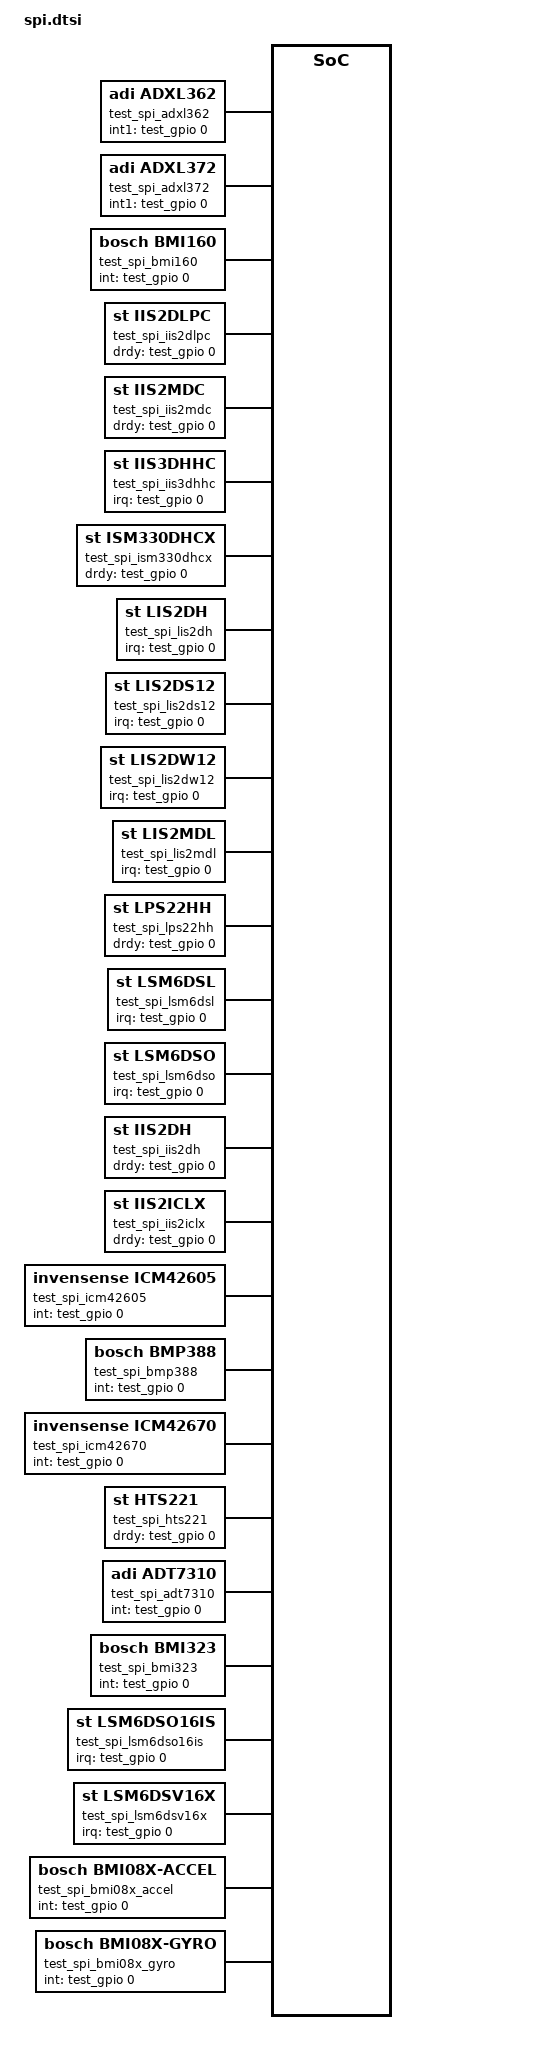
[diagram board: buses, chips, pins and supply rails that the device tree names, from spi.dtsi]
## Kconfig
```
# Copyright (c) 2023 Google LLC
# SPDX-License-Identifier: Apache-2.0

config GENERIC_SENSOR_TEST
	bool "Compile and run the generic sensor tests"
	depends on ZTEST && ZTEST_NEW_API
	help
	  Enables building and running the generic sensor test suite that will
	  iterate through the device tree and run sample path tests on any
	  sensor that supports the backend sensor emulator API.

config GENERIC_SENSOR_TEST_NUM_EXPECTED_VALS
	int "Number of expected values to use in test"
	default 5
	depends on GENERIC_SENSOR_TEST
	help
	  Controls the number of expected values to use in the generic sensor
	  test, interpolated from the sensor's reported lower and upper sample
	  range boundaries. The test will run one iteration for each expected
	  value. For example, if GENERIC_TEST_NUM_EXPECTED_VALS == 5, and the
	  sensor range is 0..100, the test will run 5 times with expected values
	  0, 25, 50, 75, and 100. These iterations are run in parallel.

source "Kconfig.zephyr"
```

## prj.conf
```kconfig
CONFIG_TEST=y
CONFIG_TEST_USERSPACE=y
CONFIG_LOG=y
CONFIG_SENSOR_LOG_LEVEL_DBG=y
CONFIG_SYS_CLOCK_TICKS_PER_SEC=1000
CONFIG_ADC=y
CONFIG_GPIO=y
CONFIG_I2C=y
CONFIG_SERIAL=y
CONFIG_SPI=y
CONFIG_W1=y
CONFIG_SENSOR=y
CONFIG_ICM42605_TRIGGER_NONE=y
```

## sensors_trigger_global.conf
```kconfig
CONFIG_ADT7310_TRIGGER_GLOBAL_THREAD=y
CONFIG_ADT7420_TRIGGER_GLOBAL_THREAD=y
CONFIG_ADXL362_TRIGGER_GLOBAL_THREAD=y
CONFIG_ADXL372_TRIGGER_GLOBAL_THREAD=y
CONFIG_AMG88XX_TRIGGER_GLOBAL_THREAD=y
CONFIG_APDS9960_TRIGGER_GLOBAL_THREAD=y
CONFIG_BMA280_TRIGGER_GLOBAL_THREAD=y
CONFIG_BMG160_TRIGGER_GLOBAL_THREAD=y
CONFIG_BMI08X_ACCEL_TRIGGER_GLOBAL_THREAD=y
CONFIG_BMI08X_GYRO_TRIGGER_GLOBAL_THREAD=y
CONFIG_BMI160_TRIGGER_GLOBAL_THREAD=y
CONFIG_BMI270_TRIGGER_GLOBAL_THREAD=y
CONFIG_BMP388_TRIGGER_GLOBAL_THREAD=y
CONFIG_BQ274XX_TRIGGER_GLOBAL_THREAD=y
CONFIG_CCS811_TRIGGER_GLOBAL_THREAD=y
CONFIG_FDC2X1X_TRIGGER_GLOBAL_THREAD=y
CONFIG_FXAS21002_TRIGGER_GLOBAL_THREAD=y
CONFIG_FXOS8700_TRIGGER_GLOBAL_THREAD=y
CONFIG_GROW_R502A_TRIGGER_GLOBAL_THREAD=y
CONFIG_HMC5883L_TRIGGER_GLOBAL_THREAD=y
CONFIG_HTS221_TRIGGER_GLOBAL_THREAD=y
CONFIG_ICM42605_TRIGGER_GLOBAL_THREAD=y
CONFIG_ICM42670_TRIGGER_GLOBAL_THREAD=y
CONFIG_ICM42688_TRIGGER_GLOBAL_THREAD=y
CONFIG_IIS2DH_TRIGGER_GLOBAL_THREAD=y
CONFIG_IIS2DLPC_TRIGGER_GLOBAL_THREAD=y
CONFIG_IIS2ICLX_TRIGGER_GLOBAL_THREAD=y
CONFIG_IIS2MDC_TRIGGER_GLOBAL_THREAD=y
CONFIG_IIS3DHHC_TRIGGER_GLOBAL_THREAD=y
CONFIG_ISL29035_TRIGGER_GLOBAL_THREAD=y
CONFIG_ISM330DHCX_TRIGGER_GLOBAL_THREAD=y
CONFIG_LIS2DH_TRIGGER_GLOBAL_THREAD=y
CONFIG_LIS2DS12_TRIGGER_GLOBAL_THREAD=y
CONFIG_LIS2DW12_TRIGGER_GLOBAL_THREAD=y
CONFIG_LIS2MDL_TRIGGER_GLOBAL_THREAD=y
CONFIG_LIS3MDL_TRIGGER_GLOBAL_THREAD=y
CONFIG_LPS22HH_TRIGGER_GLOBAL_THREAD=y
CONFIG_LSM6DSL_TRIGGER_GLOBAL_THREAD=y
CONFIG_LSM6DSO_TRIGGER_GLOBAL_THREAD=y
CONFIG_LSM6DSO16IS_TRIGGER_GLOBAL_THREAD=y
CONFIG_LSM6DSV16X_TRIGGER_GLOBAL_THREAD=y
CONFIG_MCP9808_TRIGGER_GLOBAL_THREAD=y
CONFIG_MPU6050_TRIGGER_GLOBAL_THREAD=y
CONFIG_MPU9250_TRIGGER_GLOBAL_THREAD=y
CONFIG_SHT3XD_TRIGGER_GLOBAL_THREAD=y
CONFIG_SM351LT_TRIGGER_GLOBAL_THREAD=y
CONFIG_STTS751_TRIGGER_GLOBAL_THREAD=y
CONFIG_SX9500_TRIGGER_GLOBAL_THREAD=y
CONFIG_TCN75A_TRIGGER_GLOBAL_THREAD=y
CONFIG_TMD2620_TRIGGER_GLOBAL_THREAD=y
CONFIG_TMP007_TRIGGER_GLOBAL_THREAD=y
CONFIG_VCNL4040_TRIGGER_GLOBAL_THREAD=y
CONFIG_WSEN_HIDS_TRIGGER_GLOBAL_THREAD=y
CONFIG_WSEN_TIDS_TRIGGER_GLOBAL_THREAD=y
```

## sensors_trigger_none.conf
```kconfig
CONFIG_ADT7310_TRIGGER_NONE=y
CONFIG_ADT7420_TRIGGER_NONE=y
CONFIG_ADXL362_TRIGGER_NONE=y
CONFIG_ADXL372_TRIGGER_NONE=y
CONFIG_AMG88XX_TRIGGER_NONE=y
CONFIG_APDS9960_TRIGGER_NONE=y
CONFIG_BMA280_TRIGGER_NONE=y
CONFIG_BMG160_TRIGGER_NONE=y
CONFIG_BMI08X_ACCEL_TRIGGER_NONE=y
CONFIG_BMI08X_GYRO_TRIGGER_NONE=y
CONFIG_BMI160_TRIGGER_NONE=y
CONFIG_BMI270_TRIGGER_NONE=y
CONFIG_BMP388_TRIGGER_NONE=y
CONFIG_BQ274XX_TRIGGER_NONE=y
CONFIG_CCS811_TRIGGER_NONE=y
CONFIG_FDC2X1X_TRIGGER_NONE=y
CONFIG_FXAS21002_TRIGGER_NONE=y
CONFIG_FXOS8700_TRIGGER_NONE=y
CONFIG_GROW_R502A_TRIGGER_NONE=y
CONFIG_HMC5883L_TRIGGER_NONE=y
CONFIG_HTS221_TRIGGER_NONE=y
CONFIG_ICM42605_TRIGGER_NONE=y
CONFIG_ICM42670_TRIGGER_NONE=y
CONFIG_ICM42688_TRIGGER_NONE=y
CONFIG_IIS2DH_TRIGGER_NONE=y
CONFIG_IIS2DLPC_TRIGGER_NONE=y
CONFIG_IIS2ICLX_TRIGGER_NONE=y
CONFIG_IIS2MDC_TRIGGER_NONE=y
CONFIG_IIS3DHHC_TRIGGER_NONE=y
CONFIG_ISL29035_TRIGGER_NONE=y
CONFIG_ISM330DHCX_TRIGGER_NONE=y
CONFIG_LIS2DH_TRIGGER_NONE=y
CONFIG_LIS2DS12_TRIGGER_NONE=y
CONFIG_LIS2DW12_TRIGGER_NONE=y
CONFIG_LIS2MDL_TRIGGER_NONE=y
CONFIG_LIS3MDL_TRIGGER_NONE=y
CONFIG_LPS22HH_TRIGGER_NONE=y
CONFIG_LSM6DSL_TRIGGER_NONE=y
CONFIG_LSM6DSO_TRIGGER_NONE=y
CONFIG_LSM6DSO16IS_TRIGGER_NONE=y
CONFIG_LSM6DSV16X_TRIGGER_NONE=y
CONFIG_MCP9808_TRIGGER_NONE=y
CONFIG_MPU6050_TRIGGER_NONE=y
CONFIG_MPU9250_TRIGGER_NONE=y
CONFIG_SHT3XD_TRIGGER_NONE=y
CONFIG_SM351LT_TRIGGER_NONE=y
CONFIG_STTS751_TRIGGER_NONE=y
CONFIG_SX9500_TRIGGER_NONE=y
CONFIG_TCN75A_TRIGGER_NONE=y
CONFIG_TMD2620_TRIGGER_NONE=y
CONFIG_TMP007_TRIGGER_NONE=y
CONFIG_VCNL4040_TRIGGER_NONE=y
CONFIG_WSEN_HIDS_TRIGGER_NONE=y
CONFIG_WSEN_TIDS_TRIGGER_NONE=y
```

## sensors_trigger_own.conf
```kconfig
CONFIG_ADT7310_TRIGGER_OWN_THREAD=y
CONFIG_ADT7420_TRIGGER_OWN_THREAD=y
CONFIG_ADXL362_TRIGGER_OWN_THREAD=y
CONFIG_ADXL372_TRIGGER_OWN_THREAD=y
CONFIG_AMG88XX_TRIGGER_OWN_THREAD=y
CONFIG_BMA280_TRIGGER_OWN_THREAD=y
CONFIG_BMG160_TRIGGER_OWN_THREAD=y
CONFIG_BMI08X_ACCEL_TRIGGER_OWN_THREAD=y
CONFIG_BMI08X_GYRO_TRIGGER_OWN_THREAD=y
CONFIG_BMI160_TRIGGER_OWN_THREAD=y
CONFIG_BMI270_TRIGGER_OWN_THREAD=y
CONFIG_BMP388_TRIGGER_OWN_THREAD=y
CONFIG_BQ274XX_TRIGGER_OWN_THREAD=y
CONFIG_CCS811_TRIGGER_OWN_THREAD=y
CONFIG_FDC2X1X_TRIGGER_OWN_THREAD=y
CONFIG_FXAS21002_TRIGGER_OWN_THREAD=y
CONFIG_FXOS8700_TRIGGER_OWN_THREAD=y
CONFIG_GROW_R502A_TRIGGER_OWN_THREAD=y
CONFIG_HMC5883L_TRIGGER_OWN_THREAD=y
CONFIG_HTS221_TRIGGER_OWN_THREAD=y
CONFIG_ICM42670_TRIGGER_OWN_THREAD=y
CONFIG_ICM42688_TRIGGER_OWN_THREAD=y
CONFIG_IIS2DH_TRIGGER_OWN_THREAD=y
CONFIG_IIS2DLPC_TRIGGER_OWN_THREAD=y
CONFIG_IIS2ICLX_TRIGGER_OWN_THREAD=y
CONFIG_IIS2MDC_TRIGGER_OWN_THREAD=y
CONFIG_IIS3DHHC_TRIGGER_OWN_THREAD=y
CONFIG_ISL29035_TRIGGER_OWN_THREAD=y
CONFIG_ISM330DHCX_TRIGGER_OWN_THREAD=y
CONFIG_LIS2DH_TRIGGER_OWN_THREAD=y
CONFIG_LIS2DS12_TRIGGER_OWN_THREAD=y
CONFIG_LIS2DW12_TRIGGER_OWN_THREAD=y
CONFIG_LIS2MDL_TRIGGER_OWN_THREAD=y
CONFIG_LIS3MDL_TRIGGER_OWN_THREAD=y
CONFIG_LPS22HH_TRIGGER_OWN_THREAD=y
CONFIG_LSM6DSL_TRIGGER_OWN_THREAD=y
CONFIG_LSM6DSO_TRIGGER_OWN_THREAD=y
CONFIG_LSM6DSO16IS_TRIGGER_OWN_THREAD=y
CONFIG_LSM6DSV16X_TRIGGER_OWN_THREAD=y
CONFIG_MCP9808_TRIGGER_OWN_THREAD=y
CONFIG_MPU6050_TRIGGER_OWN_THREAD=y
CONFIG_MPU9250_TRIGGER_OWN_THREAD=y
CONFIG_SHT3XD_TRIGGER_OWN_THREAD=y
CONFIG_SM351LT_TRIGGER_OWN_THREAD=y
CONFIG_STTS751_TRIGGER_OWN_THREAD=y
CONFIG_SX9500_TRIGGER_OWN_THREAD=y
CONFIG_TCN75A_TRIGGER_OWN_THREAD=y
CONFIG_TMP007_TRIGGER_OWN_THREAD=y
CONFIG_VCNL4040_TRIGGER_OWN_THREAD=y
CONFIG_WSEN_HIDS_TRIGGER_OWN_THREAD=y
CONFIG_WSEN_TIDS_TRIGGER_OWN_THREAD=y
```

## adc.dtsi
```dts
/*
 * Copyright (c) 2023 FTP Technologies
 * Copyright (c) 2023, Google LLC
 *
 * SPDX-License-Identifier: Apache-2.0
 *
 * Application overlay for ADC devices
 */

test_adc_mcp9700a: mcp9700a {
	status = "okay";
	compatible = "microchip,mcp970x";
	family = "MCP9700/9700A";
	io-channels = <&test_adc 0>;
};

test_adc_emul: adc {
	compatible = "zephyr,adc-emul";
	nchannels = <2>;
	ref-internal-mv = <3300>;
	ref-external1-mv = <5000>;
	#io-channel-cells = <1>;
	status = "okay";
};

test_ntc_thermistor_generic: ntc-thermistor-generic {
	compatible = "ntc-thermistor-generic";
	io-channels = <&adc0 0>;
	r25-ohm = <10000>;
	pullup-uv = <3300000>;
	pullup-ohm = <0>;
	pulldown-ohm = <10000>;
	connected-positive;
	zephyr,compensation-table = <0 0>, <1 1>;
};

test_epcos_b57861s0103a039: epcos-b57861s0103a039 {
	compatible = "epcos,b57861s0103a039";
	io-channels = <&adc0 0>;
	r25-ohm = <10000>;
	pullup-uv = <3300000>;
	pullup-ohm = <0>;
	pulldown-ohm = <10000>;
	connected-positive;
};
```

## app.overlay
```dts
/*
 * Copyright (c) 2020, Linaro Ltd.
 *
 * SPDX-License-Identifier: Apache-2.0
 *
 * Application overlay for testing driver builds
 *
 * Names in this file should be chosen in a way that won't conflict
 * with real-world devicetree nodes, to allow these tests to run on
 * (and be extended to test) real hardware.
 */

/ {
	test {
		#address-cells = <1>;
		#size-cells = <1>;

		test_adc: adc@adc0adc0 {
			compatible = "vnd,adc";
			reg = <0xadc0adc0 0x1000>;
			#io-channel-cells = <1>;
			#address-cells = <1>;
			#size-cells = <0>;
			status = "okay";

			channel@0 {
				reg = <0>;
				zephyr,gain = "ADC_GAIN_1";
				zephyr,reference = "ADC_REF_VDD_1";
				zephyr,acquisition-time = <ADC_ACQ_TIME_DEFAULT>;
				zephyr,input-positive = <0>;
				zephyr,resolution = <12>;
			};

			#include "adc.dtsi"
		};

		test_gpio: gpio@deadbeef {
			compatible = "vnd,gpio";
			gpio-controller;
			reg = <0xdeadbeef 0x1000>;
			#gpio-cells = <0x2>;
			status = "okay";

			#include "gpio.dtsi"
		};

		test_i2c: i2c@11112222 {
			#address-cells = <1>;
			#size-cells = <0>;
			compatible = "zephyr,i2c-emul-controller";
			reg = <0x11112222 0x1000>;
			status = "okay";
			clock-frequency = <100000>;

			#include "i2c.dtsi"
		};

		test_spi: spi@33334444 {
			#address-cells = <1>;
			#size-cells = <0>;
			compatible = "zephyr,spi-emul-controller";
			reg = <0x33334444 0x1000>;
			status = "okay";
			clock-frequency = <2000000>;

			/* one entry for every devices at spi.dtsi */
			cs-gpios = <&test_gpio 0 0>,	/* 0x00 */
				   <&test_gpio 0 0>,
				   <&test_gpio 0 0>,
				   <&test_gpio 0 0>,
				   <&test_gpio 0 0>,
				   <&test_gpio 0 0>,
				   <&test_gpio 0 0>,
				   <&test_gpio 0 0>,
				   <&test_gpio 0 0>,
				   <&test_gpio 0 0>,
				   <&test_gpio 0 0>,
				   <&test_gpio 0 0>,
				   <&test_gpio 0 0>,
				   <&test_gpio 0 0>,
				   <&test_gpio 0 0>,
				   <&test_gpio 0 0>,
				   <&test_gpio 0 0>,	/* 0x10 */
				   <&test_gpio 0 0>,
				   <&test_gpio 0 0>,
				   <&test_gpio 0 0>,
				   <&test_gpio 0 0>,
				   <&test_gpio 0 0>,
				   <&test_gpio 0 0>,
				   <&test_gpio 0 0>,
				   <&test_gpio 0 0>,
				   <&test_gpio 0 0>,
				   <&test_gpio 0 0>,
				   <&test_gpio 0 0>,
				   <&test_gpio 0 0>,
				   <&test_gpio 0 0>,
				   <&test_gpio 0 0>,
				   <&test_gpio 0 0>,
				   <&test_gpio 0 0>,	/* 0x20 */
				   <&test_gpio 0 0>,
				   <&test_gpio 0 0>,
				   <&test_gpio 0 0>,
				   <&test_gpio 0 0>;	/* 0x24 */

			#include "spi.dtsi"
		};

		test_uart: uart@55556666 {
			compatible = "vnd,serial";
			reg = <0x55556666 0x1000>;
			status = "okay";

			#include "uart.dtsi"
		};

		test_w1: w1@66660000 {
			compatible = "vnd,w1";
			reg = <0x66660000 0x1000>;
			#address-cells = <1>;
			#size-cells = <0>;
			status = "okay";

			#include "w1.dtsi"
		};

		dht22 {
			compatible = "aosong,dht";
			status = "okay";
			dio-gpios = <&test_gpio 0 0>;
			/* dht22; */
		};
	};
};

/* Put device specific modifications to properties or disabling of devices
 * here to keep the bus specific dtsi files (i2c.dtsi, spi.dtsi, etc..)
 * pristine
 */

/* disable device to conflict with i2c version */
&test_i2c_ism330dhcx {
	status = "disabled";
};

/* disable device to conflict with i2c version */
&test_spi_bme280 {
	status = "disabled";
};

/* disable device to conflict with i2c version */
&test_spi_iis2dh {
	status = "disabled";
};
```

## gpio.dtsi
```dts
/*
 * Copyright (c) 2020, Laird Connectivity
 *
 * SPDX-License-Identifier: Apache-2.0
 *
 * Application overlay for gpio devices
 */

test_gpio_sm351lt: sm351lt0 {
	compatible = "honeywell,sm351lt";
	gpios = <&test_gpio 0 0>;
};
```

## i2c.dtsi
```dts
/*
 * Copyright (c) 2020, Linaro Ltd.
 *
 * SPDX-License-Identifier: Apache-2.0
 *
 * Application overlay for i2c devices
 */

/****************************************
 * PLEASE KEEP REG ADDRESSES SEQUENTIAL *
 ***************************************/

test_i2c_adt7420: adt7420@0 {
	compatible = "adi,adt7420";
	reg = <0x0>;
	int-gpios = <&test_gpio 0 0>;
};

test_i2c_adxl345: adxl345@1 {
	compatible = "adi,adxl345";
	reg = <0x1>;
};

test_i2c_adxl372: adxl372@2 {
	compatible = "adi,adxl372";
	reg = <0x2>;
	int1-gpios = <&test_gpio 0 0>;
};

test_i2c_ccs811: ccs811@3 {
	compatible = "ams,ccs811";
	reg = <0x3>;
	wake-gpios = <&test_gpio 0 0>;
	reset-gpios = <&test_gpio 0 0>;
	irq-gpios = <&test_gpio 0 0>;
};

test_i2c_ens210: ens210@4 {
	compatible = "ams,ens210";
	reg = <0x4>;
};

test_i2c_iaqcore: iaqcore@5 {
	compatible = "ams,iaqcore";
	reg = <0x5>;
};

test_i2c_bme280: bme280@6 {
	compatible = "bosch,bme280";
	reg = <0x6>;
};

test_i2c_apds9960: apds9960@7 {
	compatible = "avago,apds9960";
	reg = <0x7>;
	int-gpios = <&test_gpio 0 0>;
};

test_i2c_bma280: bma280@8 {
	compatible = "bosch,bma280";
	reg = <0x8>;
	int1-gpios = <&test_gpio 0 0>;
	/* is-bmc150; */
};

test_i2c_bmc150_magn: bmc150_magn@9 {
	compatible = "bosch,bmc150_magn";
	reg = <0x9>;
	drdy-gpios = <&test_gpio 0 0>;
};

test_i2c_ak8975: ak8975@a {
	compatible = "asahi-kasei,ak8975";
	reg = <0xa>;
};

test_i2c_bme680: bme680@b {
	compatible = "bosch,bme680";
	reg = <0xb>;
};

test_i2c_bmg160: bmg160@c {
	compatible = "bosch,bmg160";
	reg = <0xc>;
	int-gpios = <&test_gpio 0 0>;
};

test_i2c_bmm150: bmm150@d {
	compatible = "bosch,bmm150";
	reg = <0xd>;
};

test_i2c_hmc5883l: hmc5883l@e {
	compatible = "honeywell,hmc5883l";
	reg = <0xe>;
	int-gpios = <&test_gpio 0 0>;
};

test_i2c_hp206c: hp206c@f {
	compatible = "hoperf,hp206c";
	reg = <0xf>;
};

test_i2c_th02: th02@10 {
	compatible = "hoperf,th02";
	reg = <0x10>;
};

test_i2c_mpu6050: mpu6050@11 {
	compatible = "invensense,mpu6050";
	reg = <0x11>;
	int-gpios = <&test_gpio 0 0>;
};

test_i2c_mpu9250: mpu9250@12 {
	compatible = "invensense,mpu9250";
	reg = <0x12>;
	irq-gpios = <&test_gpio 0 0>;
	gyro-sr-div = <10>;
	gyro-dlpf = <5>;
	gyro-fs = <250>;
	accel-fs = <2>;
	accel-dlpf="5.05";
};

test_i2c_ina219: ina219@13 {
	compatible = "ti,ina219";
	reg = <0x13>;
	brng = <0>;
	pg = <0>;
	sadc = <13>;
	badc = <13>;
	shunt-milliohm = <100>;
	lsb-microamp = <10>;
};

test_i2c_isl29035: isl29035@14 {
	compatible = "isil,isl29035";
	reg = <0x14>;
	int-gpios = <&test_gpio 0 0>;
};

test_i2c_max30101: max30101@15 {
	compatible = "maxim,max30101";
	reg = <0x15>;
};

test_i2c_max44009: max44009@16 {
	compatible = "maxim,max44009";
	reg = <0x16>;
	int-gpios = <&test_gpio 0 0>;
};

test_i2c_ms5607: ms5607@17 {
	compatible = "meas,ms5607";
	reg = <0x17>;
};

test_i2c_ms5837: ms5837@18 {
	compatible = "meas,ms5837";
	reg = <0x18>;
};

test_i2c_mcp9808: mcp9808@19 {
	compatible = "microchip,mcp9808";
	reg = <0x19>;
	int-gpios = <&test_gpio 0 0>;
};

test_i2c_fxas21002: fxas21002@1a {
	compatible = "nxp,fxas21002";
	reg = <0x1a>;
	int1-gpios = <&test_gpio 0 0>;
	int2-gpios = <&test_gpio 0 0>;
};

test_i2c_fxos8700: fxos8700@1b {
	compatible = "nxp,fxos8700";
	reg = <0x1b>;
	reset-gpios = <&test_gpio 0 0>;
	int1-gpios = <&test_gpio 0 0>;
	int2-gpios = <&test_gpio 0 0>;
};

test_i2c_amg88xx: amg88xx@1c {
	compatible = "panasonic,amg88xx";
	reg = <0x1c>;
	int-gpios = <&test_gpio 0 0>;
};

test_i2c_sx9500: sx9500@1d {
	compatible = "semtech,sx9500";
	reg = <0x1d>;
	int-gpios = <&test_gpio 0 0>;
};

test_i2c_sgp40: sgp40@1e {
	compatible = "sensirion,sgp40";
	reg = <0x1e>;
	enable-selftest;
};

test_i2c_sht3xd: sht3xd@1f {
	compatible = "sensirion,sht3xd";
	reg = <0x1f>;
	alert-gpios = <&test_gpio 0 0>;
};

test_i2c_sht4xd: sht4x@20 {
	compatible = "sensirion,sht4x";
	reg = <0x20>;
	repeatability = <2>;
};

test_i2c_shtc3: SHTC3@21 {
	compatible = "sensirion,shtcx";
	reg = <0x21>;
	chip = "shtc3";
	measure-mode = "normal";
	clock-stretching;
};

test_i2c_si7006: si7006@22 {
	compatible = "silabs,si7006";
	reg = <0x22>;
};

test_i2c_si7055: si7055@23 {
	compatible = "silabs,si7055";
	reg = <0x23>;
};

test_i2c_si7060: si7060@24 {
	compatible = "silabs,si7060";
	reg = <0x24>;
};

test_i2c_si7210: si7010@25 {
	compatible = "silabs,si7210";
	reg = <0x25>;
};

test_i2c_hts221: hts221@26 {
	compatible = "st,hts221";
	reg = <0x26>;
	drdy-gpios = <&test_gpio 0 0>;
};

test_i2c_iis2dlpc: iis2dlpc@27 {
	compatible = "st,iis2dlpc";
	reg = <0x27>;
	drdy-gpios = <&test_gpio 0 0>;
};

test_i2c_iis2mdc: iis2mdc@28 {
	compatible = "st,iis2mdc";
	reg = <0x28>;
	drdy-gpios = <&test_gpio 0 0>;
};

test_i2c_ism330dhcx: ism330dhcx@29 {
	compatible = "st,ism330dhcx";
	reg = <0x29>;
	drdy-gpios = <&test_gpio 0 0>;
};

test_i2c_lis2dh: lis2dh@2a {
	compatible = "st,lis2dh";
	reg = <0x2a>;
	irq-gpios = <&test_gpio 0 0>;
	/* disconnect-sdo-sa0-pull-up; */
};

test_i2c_lis2dh12: lis2dh12@2b {
	compatible = "st,lis2dh12";
	reg = <0x2b>;
	irq-gpios = <&test_gpio 0 0>;
	status = "disabled";
};

test_i2c_lis2ds12: lis2ds12@2c {
	compatible = "st,lis2ds12";
	reg = <0x2c>;
	irq-gpios = <&test_gpio 0 0>;
};

test_i2c_lis2dw12: lis2dw12@2d {
	compatible = "st,lis2dw12";
	reg = <0x2d>;
	irq-gpios = <&test_gpio 0 0>;
};

test_i2c_lis2mdl: lis2mdl@2e {
	compatible = "st,lis2mdl";
	reg = <0x2e>;
	irq-gpios = <&test_gpio 0 0>;
};

test_i2c_lis3dh: lis3dh@2f {
	compatible = "st,lis3dh";
	reg = <0x2f>;
	irq-gpios = <&test_gpio 0 0>;
	status = "disabled";
};

test_i2c_lis3mdl_magn: lis3mdl-magn@30 {
	compatible = "st,lis3mdl-magn";
	reg = <0x30>;
	irq-gpios = <&test_gpio 0 0>;
};

test_i2c_lps22hb_press: lps22hb-press@31 {
	compatible = "st,lps22hb-press";
	reg = <0x31>;
};

test_i2c_lps22hh: lps22hh@32 {
	compatible = "st,lps22hh";
	reg = <0x32>;
	drdy-gpios = <&test_gpio 0 0>;
};

test_i2c_lps25hb_press: lps25hb-press@33 {
	compatible = "st,lps25hb-press";
	reg = <0x33>;
};

test_i2c_lsm303agr_accel: lsm303agr-accel@34 {
	compatible = "st,lsm303agr-accel";
	reg = <0x34>;
	irq-gpios = <&test_gpio 0 0>;
	/* disconnect-sdo-sa0-pull-up; */
	status = "disabled";
};

test_i2c_lsm303dlhc_accel: lsm303dlhc-accel@35 {
	compatible = "st,lsm303dlhc-accel";
	reg = <0x35>;
	irq-gpios = <&test_gpio 0 0>;
	/* disconnect-sdo-sa0-pull-up; */
	status = "disabled";
};

test_i2c_lsm303dlhc_magn: lsm303dlhc-magn@36 {
	compatible = "st,lsm303dlhc-magn";
	reg = <0x36>;
};

test_i2c_lsm6ds0: lsm6ds0@37 {
	compatible = "st,lsm6ds0";
	reg = <0x37>;
};

test_i2c_lsm6dsl: lsm6dsl@38 {
	compatible = "st,lsm6dsl";
	reg = <0x38>;
	irq-gpios = <&test_gpio 0 0>;
};

test_i2c_lsm6dso: lsm6dso@39 {
	compatible = "st,lsm6dso";
	reg = <0x39>;
	irq-gpios = <&test_gpio 0 0>;
};

test_i2c_lsm9ds0_gyro: lsm9ds0-gyro@3a {
	compatible = "st,lsm9ds0-gyro";
	reg = <0x3a>;
	irq-gpios = <&test_gpio 0 0>;
};

test_i2c_lsm9ds0_mfd: lsm9ds0-mfd@3b {
	compatible = "st,lsm9ds0-mfd";
	reg = <0x3b>;
	irq-gpios = <&test_gpio 0 0>;
};

test_i2c_stts751: stts751@3c {
	compatible = "st,stts751";
	reg = <0x3c>;
	drdy-gpios = <&test_gpio 0 0>;
};

test_i2c_vl53l0x: vl53l0x@3d {
	compatible = "st,vl53l0x";
	reg = <0x3d>;
	xshut-gpios = <&test_gpio 0 0>;
};

test_i2c_hdc: hdc@3e {
	compatible = "ti,hdc";
	reg = <0x3e>;
	drdy-gpios = <&test_gpio 0 0>;
};

test_i2c_hdc2010: hdc2010@3f {
	compatible = "ti,hdc2010";
	reg = <0x3f>;
};

test_i2c_hdc2021: hdc2021@40 {
	compatible = "ti,hdc2021";
	reg = <0x40>;
};

test_i2c_hdc2022: hdc2022@41 {
	compatible = "ti,hdc2022";
	reg = <0x41>;
};

test_i2c_hdc2080: hdc2080@42 {
	compatible = "ti,hdc2080";
	reg = <0x42>;
};

test_i2c_opt3001: opt3001@43 {
	compatible = "ti,opt3001";
	reg = <0x43>;
};

test_i2c_tmp007: tmp007@44 {
	compatible = "ti,tmp007";
	reg = <0x44>;
	int-gpios = <&test_gpio 0 0>;
};

test_i2c_tmp108: tmp108@45 {
	compatible = "ti,tmp108";
	reg = <0x45>;
	alert-gpios = <&test_gpio 0 0>;
};

test_i2c_tmp112: tmp112@46 {
	compatible = "ti,tmp112";
	reg = <0x46>;
};

test_i2c_tmp116: tmp116@47 {
	compatible = "ti,tmp116";
	reg = <0x47>;
};

test_i2c_bq274xx: bq27xx@48 {
	compatible = "ti,bq274xx";
	reg = <0x48>;
	design-voltage = <3700>;
	design-capacity = <1800>;
	taper-current = <45>;
	terminate-voltage = <3000>;
	int-gpios = <&test_gpio 0 0>;
};

test_i2c_mpr: mpr@49 {
	compatible = "honeywell,mpr";
	reg = <0x49>;
};

test_i2c_dps310: dps310@4a {
	compatible = "infineon,dps310";
	reg = <0x4a>;
};

test_i2c_iis2dh: iis2dh@4b {
	compatible = "st,iis2dh";
	reg = <0x4b>;
	drdy-gpios = <&test_gpio 0 0>;
};

test_i2c_iis2iclx: iis2iclx@4c {
	compatible = "st,iis2iclx";
	reg = <0x4c>;
	drdy-gpios = <&test_gpio 0 0>;
	int-pin = <1>;
};

test_i2c_wsen_hids: wsen_hids@4d {
	compatible = "we,wsen-hids";
	reg = <0x4d>;
	drdy-gpios = <&test_gpio 0 0>;
	odr = "1";
};

test_i2c_itds: itds@4e {
	compatible = "we,wsen-itds";
	reg = <0x4e>;
	int-gpios = <&test_gpio 0 0>;
	odr = "800";
	op-mode = "high-perf";
};

test_i2c_max17055: max17055@4f {
	compatible = "maxim,max17055";
	reg = <0x4f>;
	design-capacity = <1500>;
	design-voltage = <3860>;
	desired-charging-current = <2000>;
	desired-voltage = <4400>;
	i-chg-term = <100>;
	rsense-mohms = <5>;
	v-empty = <3300>;
};

test_i2c_max17262: max17262@50 {
	compatible = "maxim,max17262";
	reg = <0x50>;
	design-voltage = <3600>;
	desired-voltage = <3600>;
	desired-charging-current = <2000>;
	design-cap = <17000>;
	empty-voltage = <3300>;
	recovery-voltage = <3880>;
	charge-voltage = <3600>;
};

test_i2c_vcnl4040: vcnl4040@51 {
	compatible = "vishay,vcnl4040";
	reg = <0x51>;
	int-gpios = <&test_gpio 0 0>;
};

test_i2c_bmi160: bmi160@52 {
	compatible = "bosch,bmi160";
	reg = <0x52>;
	int-gpios = <&test_gpio 0 0>;
};

test_i2c_bmi270: bmi270@53 {
	compatible = "bosch,bmi270";
	reg = <0x53>;
};

test_i2c_fdc2x1x: fdc2x1x@54 {
	compatible = "ti,fdc2x1x";
	reg = <0x54>;
	intb-gpios = <&test_gpio 0 0>;
	sd-gpios = <&test_gpio 0 0>;
	deglitch = <5>;
	fref = <43360>;
	channel_0 {
		rcount = <7499>;
		settlecount = <48>;
		fref-divider = <1>;
		idrive = <10>;
		fin-sel = <2>;
		inductance = <18>;
	};
};

test_i2c_bmp388: bmp388@55 {
	compatible = "bosch,bmp388";
	reg = <0x55>;
	int-gpios = <&test_gpio 0 0>;
};

test_i2c_lm75: lm75@56 {
	compatible = "lm75";
	reg = <0x56>;
};

test_i2c_ina230: ina230@57 {
	compatible = "ti,ina230";
	reg = <0x57>;
	current-lsb-microamps = <1000>;
	rshunt-micro-ohms = <1000>;
	mask = <0>;
	alert-limit = <0>;
	alert-gpios = <&test_gpio 0 0>;
};

test_i2c_lm77: lm77@58 {
	compatible = "lm77";
	reg = <0x58>;
	int-gpios = <&test_gpio 0 0>;
};

test_i2c_ina231: ina231@59 {
	compatible = "ti,ina230";
	reg = <0x59>;
	current-lsb-microamps = <1000>;
	rshunt-micro-ohms = <1000>;
	mask = <0>;
	alert-limit = <0>;
	alert-gpios = <&test_gpio 0 0>;
};

test_i2c_ina237: ina237@5a {
	compatible = "ti,ina237";
	reg = <0x5a>;
	current-lsb-microamps = <1000>;
	rshunt-micro-ohms = <1000>;
	alert-config = <0>;
	alert-gpios = <&test_gpio 0 0>;
};

test_i2c_max31875: max31875@5b {
	compatible = "maxim,max31875";
	reg = <0x5b>;
};

test_i2c_icp10125: icp10125@5c {
	compatible = "invensense,icp10125";
	reg = <0x5c>;
	temperature-measurement-mode = "normal";
	pressure-measurement-mode = "normal";
};

test_i2c_as5600: as5600@5d {
	compatible = "ams,as5600";
	reg = <0x5d>;
};

test_i2c_bh1750: bh1750@5e {
	compatible = "rohm,bh1750";
	reg = <0x5e>;
};

test_i2c_akm09918c: akm09918c@5f {
	compatible = "asahi-kasei,akm09918c";
	reg = <0x5f>;
};

test_i2c_wsen_tids: wsen_tids@60 {
	compatible = "we,wsen-tids";
	reg = <0x60>;
	int-gpios = <&test_gpio 0 0>;
	odr = <25>;
	temp-high-threshold = <0>;
	temp-low-threshold = <0>;
};

test_i2c_vl53l1x: vl53l1x@61 {
	compatible = "st,vl53l1x";
	reg = <0x61>;
	int-gpios = <&test_gpio 0 0>;
	xshut-gpios = <&test_gpio 0 0>;
};

test_i2c_tmd2620: tmd2620@62 {
	compatible = "ams,tmd2620";
	reg = <0x62>;
	int-gpios = <&test_gpio 0 0>;
	proximity-gain = <4>;
	proximity-pulse-length = <16>;
	proximity-pulse-count = <15>;
	proximity-high-threshold = <255>;
	proximity-low-threshold = <0>;
	proximity-led-drive-strength = <4>;
	proximity-interrupt-filter = <0>;
	wait-time-factor = <0>;
};

test_i2c_wsen_pads: wsen_pads@63 {
	compatible = "we,wsen-pads";
	reg = <0x63>;
	drdy-gpios = <&test_gpio 0 0>;
	odr = <1>;
};

test_i2c_s11059: s11059@64 {
	compatible = "hamamatsu,s11059";
	reg = <0x64>;
	integration-time = <546000>;
};

test_i2c_wsen_pdus: wsen_pdus@65 {
	compatible = "we,wsen-pdus";
	reg = <0x65>;
	sensor-type = <3>;
};

test_i2c_veml7700: veml7700@66 {
	compatible = "vishay,veml7700";
	reg = <0x66>;
	psm-mode = <0x03>;
};

test_i2c_ina3221: ina3221@67 {
	compatible = "ti,ina3221";
	reg = <0x67>;
	shunt-resistors = <1000 1000 1000>;
	enable-channel = <1 0 0>;
	conv-time-bus = <7>;
	conv-time-shunt = <7>;
	avg-mode = <2>;
};

test_i2c_lsm6dso16is: lsm6dso16is@68 {
	compatible = "st,lsm6dso16is";
	reg = <0x68>;
	irq-gpios = <&test_gpio 0 0>;
};

test_i2c_lsm6dsv16x: lsm6dsv16x@69 {
	compatible = "st,lsm6dsv16x";
	reg = <0x69>;
	irq-gpios = <&test_gpio 0 0>;
};

test_i2c_mcp9600: mcp9600@6a {
	compatible = "microchip,mcp9600";
	reg = <0x6a>;
};

test_i2c_tcs3400: tcs3400@6b {
	compatible = "ams,tcs3400";
	reg = <0x6b>;
	int-gpios = <&test_gpio 0 0>;
};

test_tcn75a: tcn75a@6c {
	compatible = "microchip,tcn75a";
	reg = <0x6c>;
	alert-gpios = <&test_gpio 0 0>;
};

test_i2c_bmi08x_accel: bmi08x@6d {
	compatible = "bosch,bmi08x-accel";
	reg = <0x6d>;
	int-gpios = <&test_gpio 0 0>;
	int1-map-io = <0x01>;
	int2-map-io = <0x00>;
	int1-conf-io = <0x0A>;
	int2-conf-io = <0x17>;
	accel-hz = "800";
	accel-fs = <4>;
};

test_i2c_bmi08x_gyro: bmi08x@6e {
	compatible = "bosch,bmi08x-gyro";
	reg = <0x6e>;
	int-gpios = <&test_gpio 0 0>;
	int3-4-map-io = <0x01>;
	int3-4-conf-io = <0x01>;
	gyro-hz = "1000_116";
	gyro-fs = <1000>;
};

test_i2c_ist8310@6f {
	compatible = "isentek,ist8310";
	reg = <0x6f>;
	status = "okay";
};
```

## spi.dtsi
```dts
/*
 * Copyright (c) 2020, Linaro Ltd.
 *
 * SPDX-License-Identifier: Apache-2.0
 *
 * Application overlay for spi devices
 */

/****************************************
 * PLEASE KEEP REG ADDRESSES SEQUENTIAL *
 ***************************************/

test_spi_adxl362: adxl362@0 {
	compatible = "adi,adxl362";
	reg = <0x0>;
	spi-max-frequency = <0>;
	int1-gpios = <&test_gpio 0 0>;
};

test_spi_adxl372: adxl372@1 {
	compatible = "adi,adxl372";
	reg = <0x1>;
	spi-max-frequency = <0>;
	int1-gpios = <&test_gpio 0 0>;
};

test_spi_bme280: bme280@2 {
	compatible = "bosch,bme280";
	reg = <0x2>;
	spi-max-frequency = <0>;
};

test_spi_bmi160: bmi160@3 {
	compatible = "bosch,bmi160";
	reg = <0x3>;
	spi-max-frequency = <0>;
	int-gpios = <&test_gpio 0 0>;
};

test_spi_ms5607: ms5607@4 {
	compatible = "meas,ms5607";
	reg = <0x4>;
	spi-max-frequency = <0>;
};

test_spi_iis2dlpc: iis2dlpc@5 {
	compatible = "st,iis2dlpc";
	reg = <0x5>;
	spi-max-frequency = <0>;
	drdy-gpios = <&test_gpio 0 0>;
};

test_spi_iis2mdc: iis2mdc@6 {
	compatible = "st,iis2mdc";
	reg = <0x6>;
	spi-max-frequency = <0>;
	drdy-gpios = <&test_gpio 0 0>;
};

test_spi_iis3dhhc: iis3dhhc@7 {
	compatible = "st,iis3dhhc";
	reg = <0x7>;
	spi-max-frequency = <0>;
	irq-gpios = <&test_gpio 0 0>;
};

test_spi_ism330dhcx: ism330dhcx@8 {
	compatible = "st,ism330dhcx";
	reg = <0x8>;
	spi-max-frequency = <0>;
	drdy-gpios = <&test_gpio 0 0>;
};

test_spi_lis2dh: lis2dh@9 {
	compatible = "st,lis2dh";
	reg = <0x9>;
	spi-max-frequency = <0>;
	irq-gpios = <&test_gpio 0 0>;
	/* disconnect-sdo-sa0-pull-up; */
};

test_spi_lis2ds12: lis2ds12@a {
	compatible = "st,lis2ds12";
	reg = <0xa>;
	spi-max-frequency = <0>;
	irq-gpios = <&test_gpio 0 0>;
};

test_spi_lis2dw12: lis2dw12@b {
	compatible = "st,lis2dw12";
	reg = <0xb>;
	spi-max-frequency = <0>;
	irq-gpios = <&test_gpio 0 0>;
};

test_spi_lis2mdl: lis2mdl@c {
	compatible = "st,lis2mdl";
	reg = <0xc>;
	spi-max-frequency = <0>;
	irq-gpios = <&test_gpio 0 0>;
};

test_spi_lps22hh: lps22hh@d {
	compatible = "st,lps22hh";
	reg = <0xd>;
	spi-max-frequency = <0>;
	drdy-gpios = <&test_gpio 0 0>;
};

test_spi_lsm303agr_accel: lsm303agr-accel@e {
	compatible = "st,lsm303agr-accel";
	reg = <0xe>;
	spi-max-frequency = <0>;
	irq-gpios = <&test_gpio 0 0>;
	/* disconnect-sdo-sa0-pull-up; */
	status = "disabled";
};

test_spi_lsm6dsl: lsm6dsl@f {
	compatible = "st,lsm6dsl";
	reg = <0xf>;
	spi-max-frequency = <0>;
	irq-gpios = <&test_gpio 0 0>;
};

test_spi_lsm6dso: lsm6dso@10 {
	compatible = "st,lsm6dso";
	reg = <0x10>;
	spi-max-frequency = <0>;
	irq-gpios = <&test_gpio 0 0>;
};

test_spi_iis2dh: iis2dh@11 {
	compatible = "st,iis2dh";
	reg = <0x11>;
	spi-max-frequency = <0>;
	drdy-gpios = <&test_gpio 0 0>;
};

test_spi_iis2iclx: iis2iclx@12 {
	compatible = "st,iis2iclx";
	reg = <0x12>;
	spi-max-frequency = <0>;
	drdy-gpios = <&test_gpio 0 0>;
	int-pin = <1>;
};

test_spi_icm42605: icm42605@13 {
	compatible = "invensense,icm42605";
	reg = <0x13>;
	spi-max-frequency = <0>;
	int-gpios = <&test_gpio 0 0>;
};

test_spi_max6675: max6675@14 {
	compatible = "maxim,max6675";
	reg = <0x14>;
	spi-max-frequency = <0>;
};

test_spi_bmi270: bmi270@15 {
	compatible = "bosch,bmi270";
	reg = <0x15>;
	spi-max-frequency = <0>;
};

test_spi_bmp388: bmp388@16 {
	compatible = "bosch,bmp388";
	reg = <0x16>;
	spi-max-frequency = <0>;
	int-gpios = <&test_gpio 0 0>;
};

test_spi_i3g4250d: i3g4250d@17 {
	compatible = "st,i3g4250d";
	reg = <0x17>;
	spi-max-frequency = <0>;
};

test_spi_icm42670: icm42670@18 {
	compatible = "invensense,icm42670";
	reg = <0x18>;
	spi-max-frequency = <0>;
	int-gpios = <&test_gpio 0 0>;
	accel-hz = <800>;
	accel-fs = <16>;
	gyro-hz = <800>;
	gyro-fs = <2000>;
};

test_spi_bme680: bme680@19 {
	compatible = "bosch,bme680";
	reg = <0x19>;
	spi-max-frequency = <0>;
};

test_spi_icm426888: icm42688@1a {
	compatible = "invensense,icm42688";
	reg = <0x1a>;
	spi-max-frequency = <24000000>;
	accel-hz = <32000>;
	accel-fs = <16>;
	gyro-hz = <32000>;
	gyro-fs = <2000>;
};

test_spi_max31855: max31855@1b {
	compatible = "maxim,max31855";
	reg = <0x1b>;
	spi-max-frequency = <0>;
};

test_spi_max31865: max31865@1c {
	compatible = "maxim,max31865";
	reg = <0x1c>;
	spi-max-frequency = <125000>;
	resistance-at-zero = <100>;
	resistance-reference = <430>;
	low-threshold = <6579>;
	high-threshold = <32767>;
	filter-50hz;
};

test_spi_bmm150: bmm150@1d {
	compatible = "bosch,bmm150";
	reg = <0x1d>;
	spi-max-frequency = <0>;
};

test_spi_hts221: hts221@1e {
	compatible = "st,hts221";
	reg = <0x1e>;
	spi-max-frequency = <0>;
	drdy-gpios = <&test_gpio 0 0>;
};

test_spi_adt7310: adt7310@1f {
	compatible = "adi,adt7310";
	reg = <0x1f>;
	spi-max-frequency = <0>;
	int-gpios = <&test_gpio 0 0>;
};

test_spi_bmi323: bmi323@20 {
	compatible = "bosch,bmi323";
	reg = <0x20>;
	spi-max-frequency = <8000000>;
	int-gpios = <&test_gpio 0 0>;
};

test_spi_lsm6dso16is: lsm6dso16is@21 {
	compatible = "st,lsm6dso16is";
	reg = <0x21>;
	spi-max-frequency = <0>;
	irq-gpios = <&test_gpio 0 0>;
};

test_spi_lsm6dsv16x: lsm6dsv16x@22 {
	compatible = "st,lsm6dsv16x";
	reg = <0x22>;
	spi-max-frequency = <0>;
	irq-gpios = <&test_gpio 0 0>;
};

test_spi_bmi08x_accel: bmi08x@23 {
	compatible = "bosch,bmi08x-accel";
	reg = <0x23>;
	spi-max-frequency = <0>;
	int-gpios = <&test_gpio 0 0>;
	int1-map-io = <0x01>;
	int2-map-io = <0x00>;
	int1-conf-io = <0x0A>;
	int2-conf-io = <0x17>;
	accel-hz = "800";
	accel-fs = <4>;
};

test_spi_bmi08x_gyro: bmi08x@24 {
	compatible = "bosch,bmi08x-gyro";
	reg = <0x24>;
	spi-max-frequency = <0>;
	int-gpios = <&test_gpio 0 0>;
	int3-4-map-io = <0x01>;
	int3-4-conf-io = <0x01>;
	gyro-hz = "1000_116";
	gyro-fs = <1000>;
};
```

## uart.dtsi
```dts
/*
 * Copyright (c) 2021, G-Technologies Sdn. Bhd.
 * Copyright (c) 2021 Linumiz.
 *
 * SPDX-License-Identifier: Apache-2.0
 *
 * Application overlay for uart devices
 */

test_uart_mhz19b {
	compatible = "winsen,mhz19b";
	maximum-range = <10000>;
	abc-on;
};

test_uart_pms7003 {
	compatible = "plantower,pms7003";
};

test_uart_grow_r502a {
	#address-cells=<1>;
	#size-cells=<0>;
	grow_r502a@0 {
		compatible = "hzgrow,r502a";
		reg = <0x0>;
		int-gpios = <&test_gpio 0 0>;
	};
};

test_uart_a01nyub {
	compatible = "dfrobot,a01nyub";
};
```

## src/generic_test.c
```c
/*
 * Copyright (c) 2023 Google LLC
 * SPDX-License-Identifier: Apache-2.0
 */

#include <zephyr/device.h>
#include <zephyr/drivers/emul_sensor.h>
#include <zephyr/drivers/emul.h>
#include <zephyr/ztest.h>
#include <zephyr/drivers/sensor.h>
#include <zephyr/rtio/rtio.h>
#include <zephyr/sys/bitarray.h>

#include <zephyr/logging/log.h>
LOG_MODULE_REGISTER(generic_test);

/*
 * Set up an RTIO context that can be shared for all sensors
 */

static enum sensor_channel iodev_all_channels[SENSOR_CHAN_ALL];
static struct sensor_read_config iodev_read_config = {
	.channels = iodev_all_channels,
	.max = SENSOR_CHAN_ALL,
};
RTIO_IODEV_DEFINE(iodev_read, &__sensor_iodev_api, &iodev_read_config);

/* Create the RTIO context to service the reading */
RTIO_DEFINE_WITH_MEMPOOL(sensor_read_rtio_ctx, 1, 1, 1, 64, 4);

/**
 * @brief Prepare the RTIO context for next test
 */
static void before(void *args)
{
	ARG_UNUSED(args);

	/* Clear the array of requested channels */
	memset(iodev_all_channels, 0, sizeof(iodev_all_channels));

	/* Reset the channel count */
	iodev_read_config.count = 0;

	/* Remove previous sensor pointer */
	iodev_read_config.sensor = NULL;

	/* Wipe the mempool by marking every block free */
	zassert_ok(sys_bitarray_clear_region(sensor_read_rtio_ctx_block_pool.mempool->bitmap,
					     sensor_read_rtio_ctx_block_pool.mempool->num_blocks,
					     0));

	/* Flush the SQ and CQ */
	rtio_sqe_drop_all(&sensor_read_rtio_ctx);
	while (rtio_cqe_consume(&sensor_read_rtio_ctx))
		;
}

/**
 * @brief Helper function the carries out the generic sensor test for a given sensor device.
 *        Verifies that the device has a suitable emulator that implements the backend API and
 *        skips the test gracefully if not.
 */
static void run_generic_test(const struct device *dev)
{
	zassert_not_null(dev, "Cannot get device pointer. Is this driver properly instantiated?");

	const struct emul *emul = emul_get_binding(dev->name);

	/* Skip this sensor if there is no emulator loaded. */
	if (!emul) {
		ztest_test_skip();
	}

	/* Also skip if this emulator does not implement the backend API. */
	if (!emul_sensor_backend_is_supported(emul)) {
		ztest_test_skip();
	}

	/*
	 * Begin the actual test sequence
	 */

	static struct {
		bool supported;
		bool received;
		q31_t expected_values[CONFIG_GENERIC_SENSOR_TEST_NUM_EXPECTED_VALS];
		q31_t epsilon;
		int8_t expected_value_shift;
	} channel_table[SENSOR_CHAN_ALL];

	memset(channel_table, 0, sizeof(channel_table));

	/* Discover supported channels on this device and fill out our sensor read request */
	for (enum sensor_channel ch = 0; ch < ARRAY_SIZE(channel_table); ch++) {
		if (SENSOR_CHANNEL_3_AXIS(ch)) {
			continue;
		}

		q31_t lower, upper;
		int8_t shift;

		if (emul_sensor_backend_get_sample_range(emul, ch, &lower, &upper,
							 &channel_table[ch].epsilon, &shift) == 0) {
			/* This channel is supported */
			channel_table[ch].supported = true;

			LOG_INF("CH %d: lower=%d, upper=%d, eps=%d, shift=%d", ch, lower, upper,
				channel_table[ch].epsilon, shift);

			/* Add to the list of channels to read */
			iodev_all_channels[iodev_read_config.count++] = ch;

			/* Generate a set of CONFIG_GENERIC_SENSOR_TEST_NUM_EXPECTED_VALS test
			 * values.
			 */

			channel_table[ch].expected_value_shift = shift;
			for (size_t i = 0; i < CONFIG_GENERIC_SENSOR_TEST_NUM_EXPECTED_VALS; i++) {
				channel_table[ch].expected_values[i] =
					lower +
					(i * ((int64_t)upper - lower) /
					 (CONFIG_GENERIC_SENSOR_TEST_NUM_EXPECTED_VALS - 1));
				LOG_INF("CH %d: Expected value %d/%d: %d", ch, i + 1,
					CONFIG_GENERIC_SENSOR_TEST_NUM_EXPECTED_VALS,
					channel_table[ch].expected_values[i]);
			}
		}
	}
	iodev_read_config.sensor = dev;

	/* Do a read of all channels for quantity CONFIG_GENERIC_SENSOR_TEST_NUM_EXPECTED_VALS
	 * iterations.
	 */

	for (size_t iteration = 0; iteration < CONFIG_GENERIC_SENSOR_TEST_NUM_EXPECTED_VALS;
	     iteration++) {
		int rv;

		/* Reset received flag */
		for (size_t i = 0; i < ARRAY_SIZE(channel_table); i++) {
			channel_table[i].received = false;
		}

		/* Set this iteration's expected values in emul for every supported channel */
		for (size_t i = 0; i < iodev_read_config.count; i++) {
			enum sensor_channel ch = iodev_all_channels[i];

			rv = emul_sensor_backend_set_channel(
				emul, ch, channel_table[ch].expected_values[iteration],
				channel_table[ch].expected_value_shift);
			zassert_ok(
				rv,
				"Cannot set value 0x%08x on channel %d (error %d, iteration %d/%d)",
				channel_table[i].expected_values[iteration], ch, rv, iteration + 1,
				CONFIG_GENERIC_SENSOR_TEST_NUM_EXPECTED_VALS);
		}

		/* Perform the actual sensor read */
		rv = sensor_read(&iodev_read, &sensor_read_rtio_ctx, NULL);
		zassert_ok(rv, "Could not read sensor (error %d, iteration %d/%d)", rv,
			   iteration + 1, CONFIG_GENERIC_SENSOR_TEST_NUM_EXPECTED_VALS);

		/* Wait for a CQE */
		struct rtio_cqe *cqe = rtio_cqe_consume_block(&sensor_read_rtio_ctx);

		zassert_ok(cqe->result, "CQE has failed status (error %d, iteration %d/%d)",
			   cqe->result, iteration + 1,
			   CONFIG_GENERIC_SENSOR_TEST_NUM_EXPECTED_VALS);

		uint8_t *buf = NULL;
		uint32_t buf_len = 0;

		/* Cache the data from the CQE */
		rtio_cqe_get_mempool_buffer(&sensor_read_rtio_ctx, cqe, &buf, &buf_len);

		/* Release the CQE */
		rtio_cqe_release(&sensor_read_rtio_ctx, cqe);

		enum sensor_channel channel;
		sensor_frame_iterator_t fit = {0};
		sensor_channel_iterator_t cit = {0};
		const struct sensor_decoder_api *decoder;
		int8_t shift;
		q31_t q;

		zassert_ok(sensor_get_decoder(dev, &decoder));

		/* Decode the buffer and verify all channels */
		while (decoder->decode(buf, &fit, &cit, &channel, &q, 1) > 0) {
			zassert_true(channel_table[channel].supported);
			zassert_false(channel_table[channel].received);
			channel_table[channel].received = true;

			zassert_ok(decoder->get_shift(buf, channel, &shift));

			/* Align everything to be a 64-bit Q32.32 number for comparison */
			int64_t expected_shifted =
				(int64_t)channel_table[channel].expected_values[iteration]
				<< channel_table[channel].expected_value_shift;
			int64_t actual_shifted = (int64_t)q << shift;
			int64_t epsilon_shifted = (int64_t)channel_table[channel].epsilon
						  << channel_table[channel].expected_value_shift;

			zassert_within(expected_shifted, actual_shifted, epsilon_shifted,
				       "Expected %lld, got %lld (shift %d, ch %d, iteration %d/%d, "
				       "Error %lld, Epsilon %lld)",
				       expected_shifted, actual_shifted, shift, channel,
				       iteration + 1, CONFIG_GENERIC_SENSOR_TEST_NUM_EXPECTED_VALS,
				       expected_shifted - actual_shifted, epsilon_shifted);
		}

		/* Release the memory */
		rtio_release_buffer(&sensor_read_rtio_ctx, buf, buf_len);

		/* Ensure all supported channels were received */
		int missing_channel_count = 0;

		for (size_t i = 0; i < ARRAY_SIZE(channel_table); i++) {
			if (channel_table[i].supported && !channel_table[i].received) {
				missing_channel_count++;
			}
		}

		zassert_equal(0, missing_channel_count);
	}
}

#define DECLARE_ZTEST_PER_DEVICE(n)                                                                \
	ZTEST(generic, test_##n)                                                                   \
	{                                                                                          \
		run_generic_test(DEVICE_DT_GET(n));                                                \
	}

/* Iterate through each of the emulated buses and create a test for each device. */
DT_FOREACH_CHILD_STATUS_OKAY(DT_NODELABEL(test_i2c), DECLARE_ZTEST_PER_DEVICE)
DT_FOREACH_CHILD_STATUS_OKAY(DT_NODELABEL(test_spi), DECLARE_ZTEST_PER_DEVICE)

ZTEST_SUITE(generic, NULL, NULL, before, NULL, NULL);
```
